AUTOSAR XML (schema 4-3-0)
standard types defined: uint16
package /Demo/DataTypes
  impl type Speed_T: category=VALUE
  app type VehicleSpeed: category=VALUE
package /Demo/Interfaces
  sender receiver interface SpeedIf
    data Speed: type=Speed_T
  client server interface DiagIf
    operation ReadDtc
      arg Code: direction=OUT
package /Demo/Components
  application sw component type SpeedSensor
    provide port SpeedOut: provided-interface=SpeedIf
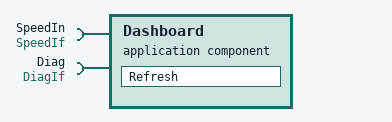
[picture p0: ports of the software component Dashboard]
  application sw component type Dashboard
    require port SpeedIn: required-interface=SpeedIf
    require port Diag: required-interface=DiagIf
    behavior DashboardBehavior
      runnable Refresh
  composition sw component type Cluster
package /Demo/System
  system Vehicle
  ecu instance BodyEcu
  ecu instance ClusterEcu
  can cluster Can1
